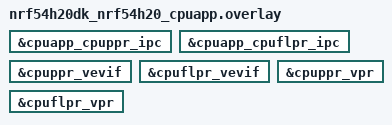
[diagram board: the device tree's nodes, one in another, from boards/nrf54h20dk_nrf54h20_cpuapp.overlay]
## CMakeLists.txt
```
#
# Copyright (c) 2026 Nordic Semiconductor ASA
#
# SPDX-License-Identifier: Apache-2.0
#

cmake_minimum_required(VERSION 3.28.0)

find_package(Zephyr REQUIRED HINTS $ENV{ZEPHYR_BASE})

if(NOT (CONFIG_BOARD_NRF54H20DK_NRF54H20_CPUAPP))
  message(FATAL_ERROR "${BOARD}/${BOARD_QUALIFIERS} is not supported for this sample")
endif()

project(coresight_stm_shell)

target_sources(app PRIVATE src/main.c)
```

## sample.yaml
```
# Copyright (c) 2026 Nordic Semiconductor ASA
# SPDX-License-Identifier: Apache-2.0

sample:
  name: Coresight STM logging with remote shell on nRF54H20

common:
  tags:
    - logging
    - shell
  platform_allow:
    - nrf54h20dk/nrf54h20/cpuapp
  integration_platforms:
    - nrf54h20dk/nrf54h20/cpuapp

tests:
  sample.boards.nrf.coresight_stm_shell:
    required_snippets:
      - nordic-log-stm
    harness: pytest
```

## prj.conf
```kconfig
# Copyright (c) 2026 Nordic Semiconductor ASA
# SPDX-License-Identifier: Apache-2.0

CONFIG_SHELL=y
CONFIG_SHELL_REMOTE=y
CONFIG_SHELL_REMOTE_PPR=y
CONFIG_SHELL_REMOTE_FLPR=y
CONFIG_SHELL_REMOTE_RADIO=y
CONFIG_HEAP_MEM_POOL_SIZE=2048

CONFIG_LOG_RUNTIME_FILTERING=y
CONFIG_LOG_CMDS=y

CONFIG_SOC_NRF54H20_CPURAD_ENABLE=y

# kwork must start before ETR logging
CONFIG_KERNEL_INIT_PRIORITY_DEFAULT=0

# Allow receiving longer messages over IPC
CONFIG_PBUF_RX_READ_BUF_SIZE=256
```

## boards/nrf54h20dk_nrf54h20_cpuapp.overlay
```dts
/*
 * Copyright (c) 2026 Nordic Semiconductor ASA
 *
 * SPDX-License-Identifier: Apache-2.0
 *
 * Enable CPUPPR / CPUFLPR VPRs and IPC between cpuapp and each coprocessor (icmsg).
 * CPURAD IPC uses ipc0 in board DTS; CPURAD core boot uses Kconfig on cpuapp.
 */

&cpuapp_cpuppr_ipc {
	status = "okay";
};

&cpuapp_cpuflpr_ipc {
	status = "okay";
};

&cpuppr_vevif {
	status = "okay";
};

&cpuflpr_vevif {
	status = "okay";
};

&cpuppr_vpr {
	status = "okay";
};

&cpuflpr_vpr {
	status = "okay";
};
```

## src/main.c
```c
/*
 * Copyright (c) 2026 Nordic Semiconductor ASA
 *
 * SPDX-License-Identifier: Apache-2.0
 */

#include <zephyr/kernel.h>
#include <zephyr/shell/shell.h>
#include <zephyr/shell/shell_remote_common.h>
#include <zephyr/logging/log_ctrl.h>
#include <zephyr/logging/log.h>
LOG_MODULE_REGISTER(app, LOG_LEVEL_DBG);

static int cmd_ping(const struct shell *sh, size_t argc, char **argv)
{
	ARG_UNUSED(argc);
	ARG_UNUSED(argv);

	LOG_ERR("error %d", 100);
	LOG_WRN("warning %lld", 0x1234567890LL);
	LOG_INF("info %s", "test");
	LOG_DBG("debug %d %d", 1000, 100);
	shell_print(sh, "pong %s", CONFIG_BOARD_TARGET);
	return 0;
}

SHELL_CMD_REGISTER(ping, NULL, "Demo command", cmd_ping);

int main(void)
{
#ifndef CONFIG_MULTITHREADING
	/* If multithreading is not enabled, we need to process the shell commands manually. */
	while (1) {
		shell_remote_cmd_process();
		if (LOG_PROCESS() == false) {
			k_cpu_idle();
		}
	}
#endif
	return 0;
}
```
